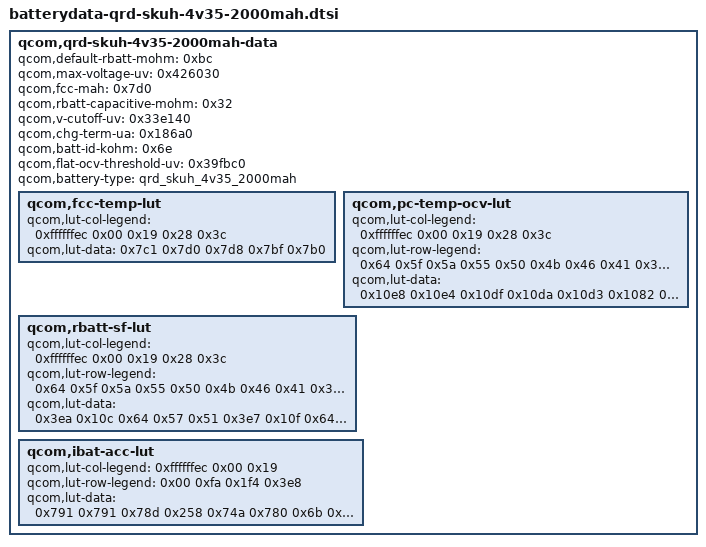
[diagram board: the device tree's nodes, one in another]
/* Copyright (c) 2016, The Linux Foundation. All rights reserved.
 *
 * This program is free software; you can redistribute it and/or modify
 * it under the terms of the GNU General Public License version 2 and
 * only version 2 as published by the Free Software Foundation.
 *
 * This program is distributed in the hope that it will be useful,
 * but WITHOUT ANY WARRANTY; without even the implied warranty of
 * MERCHANTABILITY or FITNESS FOR A PARTICULAR PURPOSE.  See the
 * GNU General Public License for more details.
 */

qcom,qrd-skuh-4v35-2000mah-data {
	qcom,default-rbatt-mohm = <0xbc>;
	qcom,max-voltage-uv = <0x426030>;
	qcom,fcc-mah = <0x7d0>;
	qcom,rbatt-capacitive-mohm = <0x32>;
	qcom,v-cutoff-uv = <0x33e140>;
	qcom,chg-term-ua = <0x186a0>;
	qcom,batt-id-kohm = <0x6e>;
	qcom,flat-ocv-threshold-uv = <0x39fbc0>;
	qcom,battery-type = "qrd_skuh_4v35_2000mah";

	qcom,fcc-temp-lut {
		qcom,lut-col-legend = <0xffffffec 0x00 0x19 0x28 0x3c>;
		qcom,lut-data = <0x7c1 0x7d0 0x7d8 0x7bf 0x7b0>;
	};

	qcom,pc-temp-ocv-lut {
		qcom,lut-col-legend = <0xffffffec 0x00 0x19 0x28 0x3c>;
		qcom,lut-row-legend = <0x64 0x5f 0x5a 0x55 0x50 0x4b 0x46 0x41 0x3c 0x37 0x32 0x2d 0x28 0x23 0x1e 0x19 0x14 0x0f 0x0a 0x09 0x08 0x07 0x06 0x05 0x04 0x03 0x02 0x01 0x00>;
		qcom,lut-data = <0x10e8 0x10e4 0x10df 0x10da 0x10d3 0x1082 0x1096 0x1099 0x1099 0x1095 0x103c 0x105b 0x1061 0x1062 0x105f 0xfff 0x1025 0x102c 0x102f 0x102c 0xfc5 0xff0 0xff9 0xffd 0xffb 0xf91 0xfbc 0xfc9 0xfce 0xfcc 0xf60 0xf88 0xf9d 0xfa2 0xfa2 0xf37 0xf5c 0xf70 0xf78 0xf78 0xf10 0xf35 0xf42 0xf49 0xf4a 0xeee 0xf15 0xf1d 0xf23 0xf24 0xed1 0xef7 0xf01 0xf07 0xf08 0xeb8 0xee0 0xeeb 0xef0 0xef0 0xea3 0xecb 0xed7 0xedd 0xedd 0xe8f 0xebc 0xec7 0xecc 0xecb 0xe7d 0xeaf 0xeb6 0xeb5 0xead 0xe6d 0xea0 0xea2 0xe9c 0xe92 0xe5a 0xe8c 0xe8f 0xe88 0xe7c 0xe43 0xe6b 0xe74 0xe6c 0xe60 0xe1a 0xe4b 0xe59 0xe58 0xe4c 0xe11 0xe46 0xe56 0xe54 0xe49 0xe05 0xe40 0xe50 0xe4f 0xe43 0xdf4 0xe36 0xe46 0xe42 0xe33 0xddd 0xe23 0xe2f 0xe27 0xe15 0xdc0 0xe01 0xe08 0xdfe 0xdec 0xd9a 0xdd1 0xdd4 0xdcb 0xdb8 0xd65 0xd91 0xd91 0xd88 0xd75 0xd1b 0xd3c 0xd35 0xd2d 0xd19 0xca7 0xcbb 0xc9f 0xca3 0xc90 0xbb8 0xbb8 0xbb8 0xbb8 0xbb8>;
	};

	qcom,rbatt-sf-lut {
		qcom,lut-col-legend = <0xffffffec 0x00 0x19 0x28 0x3c>;
		qcom,lut-row-legend = <0x64 0x5f 0x5a 0x55 0x50 0x4b 0x46 0x41 0x3c 0x37 0x32 0x2d 0x28 0x23 0x1e 0x19 0x14 0x0f 0x0a 0x09 0x08 0x07 0x06 0x05 0x04 0x03 0x02 0x01 0x00>;
		qcom,lut-data = <0x3ea 0x10c 0x64 0x57 0x51 0x3e7 0x10f 0x64 0x58 0x52 0x3e7 0x10f 0x66 0x58 0x52 0x3dc 0x112 0x6a 0x5b 0x54 0x3cf 0x113 0x6e 0x5e 0x55 0x3c7 0x10f 0x73 0x61 0x56 0x3c9 0x105 0x79 0x65 0x59 0x3ce 0x100 0x78 0x69 0x5b 0x3d2 0xfe 0x6b 0x60 0x56 0x3dc 0x101 0x65 0x59 0x53 0x3f9 0x104 0x66 0x59 0x52 0x416 0x10b 0x69 0x5c 0x53 0x43d 0x113 0x6c 0x5e 0x55 0x468 0x11e 0x70 0x61 0x57 0x4a3 0x12a 0x70 0x5e 0x54 0x4f4 0x136 0x6c 0x5a 0x53 0x54f 0x142 0x6d 0x5c 0x53 0x5e1 0x148 0x6e 0x5b 0x52 0x6f9 0x173 0x6f 0x5e 0x54 0x673 0x14b 0x70 0x5e 0x54 0x519 0x156 0x71 0x5d 0x54 0x556 0x15f 0x72 0x5d 0x53 0x5aa 0x16c 0x71 0x5c 0x52 0x62e 0x175 0x70 0x5c 0x54 0x76c 0x18e 0x71 0x5e 0x55 0xa33 0x1bb 0x75 0x5f 0x56 0xff0 0x207 0x7b 0x66 0x5d 0x1f8a 0x2b8 0x99 0xab 0x95 0x77c0 0x11c3 0x2546 0x1ca3 0x17fa>;
	};

	qcom,ibat-acc-lut {
		qcom,lut-col-legend = <0xffffffec 0x00 0x19>;
		qcom,lut-row-legend = <0x00 0xfa 0x1f4 0x3e8>;
		qcom,lut-data = <0x791 0x791 0x78d 0x258 0x74a 0x780 0x6b 0x642 0x76a 0x0b 0x36e 0x731>;
	};
};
